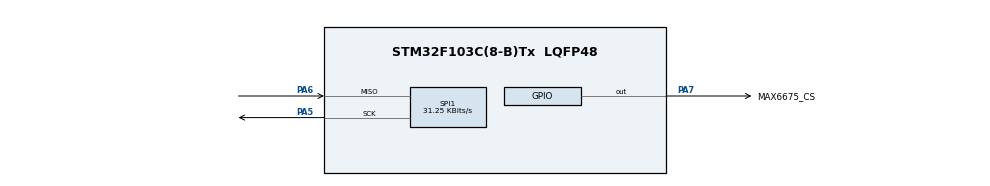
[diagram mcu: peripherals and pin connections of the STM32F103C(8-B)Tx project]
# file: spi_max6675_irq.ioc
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Mcu.Family=STM32F1
Mcu.Name=STM32F103C(8-B)Tx
Mcu.Package=LQFP48
NVIC.PriorityGroup=NVIC_PRIORITYGROUP_4
NVIC.SPI1_IRQn=true\:0\:0\:false\:false\:true\:true\:true\:true
PA13.Mode=Serial_Wire
PA13.Signal=SYS_JTMS-SWDIO
PA14.Mode=Serial_Wire
PA14.Signal=SYS_JTCK-SWCLK
PA5.Mode=RX_Only_Simplex_Unidirect_Master
PA5.Signal=SPI1_SCK
PA6.Mode=RX_Only_Simplex_Unidirect_Master
PA6.Signal=SPI1_MISO
PA7.GPIO_Label=MAX6675_CS
PA7.PinState=GPIO_PIN_SET
PA7.Signal=GPIO_Output
PC14-OSC32_IN.Mode=LSE-External-Oscillator
PC14-OSC32_IN.Signal=RCC_OSC32_IN
PC15-OSC32_OUT.Mode=LSE-External-Oscillator
PC15-OSC32_OUT.Signal=RCC_OSC32_OUT
PD0-OSC_IN.Mode=HSE-External-Oscillator
PD0-OSC_IN.Signal=RCC_OSC_IN
PD1-OSC_OUT.Mode=HSE-External-Oscillator
PD1-OSC_OUT.Signal=RCC_OSC_OUT
ProjectManager.HeapSize=0x200
ProjectManager.StackSize=0x400
ProjectManager.TargetToolchain=STM32CubeIDE
RCC.APB1Freq_Value=8000000
RCC.APB2Freq_Value=8000000
SPI1.BaudRatePrescaler=SPI_BAUDRATEPRESCALER_256
SPI1.CLKPhase=SPI_PHASE_2EDGE
SPI1.CLKPolarity=SPI_POLARITY_LOW
SPI1.CalculateBaudRate=31.25 KBits/s
SPI1.DataSize=SPI_DATASIZE_16BIT
SPI1.Direction=SPI_DIRECTION_2LINES_RXONLY
SPI1.Mode=SPI_MODE_MASTER
SPI1.VirtualType=VM_MASTER
board=custom

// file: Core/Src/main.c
/* USER CODE BEGIN Header */
/**
 ******************************************************************************
 * @file           : main.c
 * @brief          : Main program body
 ******************************************************************************
 * @attention
 *
 * Copyright (c) 2023 STMicroelectronics.
 * All rights reserved.
 *
 * This software is licensed under terms that can be found in the LICENSE file
 * in the root directory of this software component.
 * If no LICENSE file comes with this software, it is provided AS-IS.
 *
 ******************************************************************************
 */
/* USER CODE END Header */
#include "main.h"

 SPI_HandleTypeDef hspi1;

/* USER CODE BEGIN PV */
uint8_t rx_buffer[2];
uint32_t temperature;
uint32_t count_ms, rx_done;
/* USER CODE END PV */

void SystemClock_Config(void);
static void MX_GPIO_Init(void);
static void MX_SPI1_Init(void);

/* USER CODE BEGIN 0 */
void HAL_IncTick(void) {
	uwTick += uwTickFreq;
	count_ms++;
}
void HAL_SPI_RxCpltCallback(SPI_HandleTypeDef *hspi) {
	rx_done = 1;
}
/* USER CODE END 0 */

int main(void)
{

  /* MCU Configuration--------------------------------------------------------*/

  /* Reset of all peripherals, Initializes the Flash interface and the Systick. */
  HAL_Init();

  /* Configure the system clock */
  SystemClock_Config();

  /* Initialize all configured peripherals */
  MX_GPIO_Init();
  MX_SPI1_Init();

  /* Infinite loop */
  /* USER CODE BEGIN WHILE */
	while (1) {
		if (count_ms >= 1000) {
			count_ms = 0;
			HAL_GPIO_WritePin(MAX6675_CS_GPIO_Port, MAX6675_CS_Pin, GPIO_PIN_RESET);
			HAL_SPI_Receive_IT(&hspi1, rx_buffer, 1);
		}
		if (rx_done) {
			rx_done = 0;
			HAL_GPIO_WritePin(MAX6675_CS_GPIO_Port, MAX6675_CS_Pin, GPIO_PIN_SET);
			temperature = (((rx_buffer[1] << 8) + rx_buffer[0]) >> 3)*0.25;
		}
		__WFI();
    /* USER CODE END WHILE */

	}
}

void SystemClock_Config(void)
{
  RCC_OscInitTypeDef RCC_OscInitStruct = {0};
  RCC_ClkInitTypeDef RCC_ClkInitStruct = {0};

  /** Initializes the RCC Oscillators according to the specified parameters
  * in the RCC_OscInitTypeDef structure.
  */
  RCC_OscInitStruct.OscillatorType = RCC_OSCILLATORTYPE_HSI;
  RCC_OscInitStruct.HSIState = RCC_HSI_ON;
  RCC_OscInitStruct.HSICalibrationValue = RCC_HSICALIBRATION_DEFAULT;
  RCC_OscInitStruct.PLL.PLLState = RCC_PLL_NONE;
  if (HAL_RCC_OscConfig(&RCC_OscInitStruct) != HAL_OK)
  {
    Error_Handler();
  }

  /** Initializes the CPU, AHB and APB buses clocks
  */
  RCC_ClkInitStruct.ClockType = RCC_CLOCKTYPE_HCLK|RCC_CLOCKTYPE_SYSCLK
                              |RCC_CLOCKTYPE_PCLK1|RCC_CLOCKTYPE_PCLK2;
  RCC_ClkInitStruct.SYSCLKSource = RCC_SYSCLKSOURCE_HSI;
  RCC_ClkInitStruct.AHBCLKDivider = RCC_SYSCLK_DIV1;
  RCC_ClkInitStruct.APB1CLKDivider = RCC_HCLK_DIV1;
  RCC_ClkInitStruct.APB2CLKDivider = RCC_HCLK_DIV1;

  if (HAL_RCC_ClockConfig(&RCC_ClkInitStruct, FLASH_LATENCY_0) != HAL_OK)
  {
    Error_Handler();
  }
}

static void MX_SPI1_Init(void)
{

  /* SPI1 parameter configuration*/
  hspi1.Instance = SPI1;
  hspi1.Init.Mode = SPI_MODE_MASTER;
  hspi1.Init.Direction = SPI_DIRECTION_2LINES_RXONLY;
  hspi1.Init.DataSize = SPI_DATASIZE_16BIT;
  hspi1.Init.CLKPolarity = SPI_POLARITY_LOW;
  hspi1.Init.CLKPhase = SPI_PHASE_2EDGE;
  hspi1.Init.NSS = SPI_NSS_SOFT;
  hspi1.Init.BaudRatePrescaler = SPI_BAUDRATEPRESCALER_256;
  hspi1.Init.FirstBit = SPI_FIRSTBIT_MSB;
  hspi1.Init.TIMode = SPI_TIMODE_DISABLE;
  hspi1.Init.CRCCalculation = SPI_CRCCALCULATION_DISABLE;
  hspi1.Init.CRCPolynomial = 10;
  if (HAL_SPI_Init(&hspi1) != HAL_OK)
  {
    Error_Handler();
  }

}

static void MX_GPIO_Init(void)
{
  GPIO_InitTypeDef GPIO_InitStruct = {0};

  /* GPIO Ports Clock Enable */
  __HAL_RCC_GPIOC_CLK_ENABLE();
  __HAL_RCC_GPIOD_CLK_ENABLE();
  __HAL_RCC_GPIOA_CLK_ENABLE();

  /*Configure GPIO pin Output Level */
  HAL_GPIO_WritePin(MAX6675_CS_GPIO_Port, MAX6675_CS_Pin, GPIO_PIN_SET);

  /*Configure GPIO pin : MAX6675_CS_Pin */
  GPIO_InitStruct.Pin = MAX6675_CS_Pin;
  GPIO_InitStruct.Mode = GPIO_MODE_OUTPUT_PP;
  GPIO_InitStruct.Pull = GPIO_NOPULL;
  GPIO_InitStruct.Speed = GPIO_SPEED_FREQ_LOW;
  HAL_GPIO_Init(MAX6675_CS_GPIO_Port, &GPIO_InitStruct);

}

void Error_Handler(void)
{
	__disable_irq();
	while (1) {
	}
}
